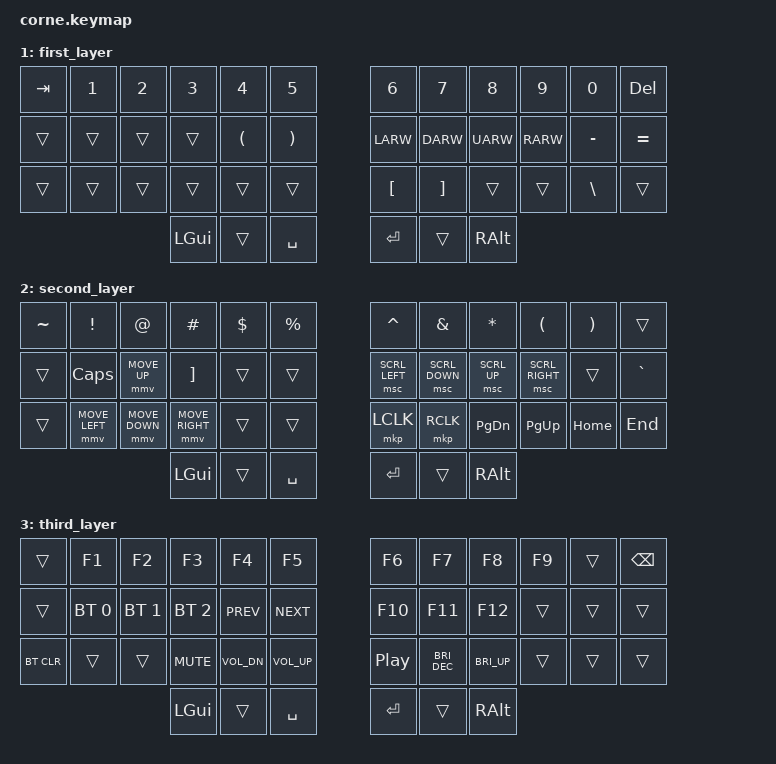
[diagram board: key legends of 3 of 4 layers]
/*
 * Copyright (c) 2020 The ZMK Contributors
 *
 * SPDX-License-Identifier: MIT
 */

#include <behaviors.dtsi>
#include <dt-bindings/zmk/keys.h>
#include <dt-bindings/zmk/bt.h>
#include <dt-bindings/zmk/outputs.h>
#include <dt-bindings/zmk/pointing.h>

// Home row mods macro
#define HRML(k1,k2,k3,k4) &ht LSHFT k1 &ht LCTRL k2  &ht LALT k3   &ht LGUI k4
#define HRMR(k1,k2,k3,k4) &ht RGUI k1  &ht LALT k2   &ht RCTRL k3  &ht RSHFT k4

#define DFLT 0
#define FRST 1
#define SCND 2
#define THRD 3

/ {
    behaviors {
         ht: hold_tap {
            label = "hold_tap";
            compatible = "zmk,behavior-hold-tap";
            #binding-cells = <2>;
            flavor = "tap-preferred";
            tapping-term-ms = <220>;
            quick-tap-ms = <150>;
            global-quick-tap;
            bindings = <&kp>, <&kp>;
        };
    };
        
    keymap {
            compatible = "zmk,keymap";

            default_layer {
    // -----------------------------------------------------------------------------------------
    // | ESC  |  Q  |  W  |  E  |  R  |  T  |   |  Y  |  U   |  I  |  O  |  P  | BSPC |
    // | SHFT |  A  |  S  |  D  |  F  |  G  |   |  H  |  J   |  K  |  L  |  ;  |  '   |
    // | CTRL |  Z  |  X  |  C  |  V  |  B  |   |  N  |  M   |  ,  |  .  |  /  | ENT  |
    //                    | GUI | LWR | SPC |   | ENT | RSE  | ALT |
                        bindings = <
    &kp ESC    &kp Q &kp W &kp E &kp R &kp T             &kp Y &kp U   &kp I      &kp O   &kp P    &kp BSPC
    &kp LSHFT HRML(A,   S,    D,   F) &kp G             &kp H HRMR(J,     K,         L,   SEMI)   &kp SQT
    &kp LCTRL &kp Z &kp X &kp C &kp V &kp B             &kp N &kp M   &kp COMMA  &kp PERIOD &kp FSLH &kp RET
                  &kp LGUI &mo FRST    &lt THRD SPACE   &kp RET &mo SCND &kp RALT
                        >;
                };
                first_layer {
    // -----------------------------------------------------------------------------------------
    // |  TAB |  1   |  2  |  3  |  4  |  5  |   |  6  |  7  |  8  |  9  |  0  | DEL  |
    // |      |      |     |     |  (  |  )  |   | LFT | DWN |  UP | RGT |  -_ |  +=  |
    // | SHFT |      |     |     |     |     |   |  [  |  ]  |     |     |  /| |      |
    //                    | GUI |     | SPC |   | ENT |     | ALT |
                        bindings = <
    &kp TAB    &kp N1    &kp N2    &kp N3     &kp N4       &kp N5         &kp N6   &kp N7    &kp N8   &kp N9    &kp N0    &kp DEL
    &trans     &trans  &trans    &trans     &kp LPAR     &kp RPAR       &kp LARW &kp DARW  &kp UARW &kp RARW  &kp MINUS &kp EQUAL
    &trans     &trans    &trans    &trans     &trans       &trans         &kp LBKT &kp RBKT &trans   &trans    &kp BSLH     &trans
                                   &kp LGUI     &trans     &kp SPACE    &kp RET  &trans   &kp RALT
                        >;
                };
                second_layer {
    // -----------------------------------------------------------------------------------------
    // |  ˜   |  !    |  @    |  #     |  $  |  %  |   |  ^        |  &         |  *      |  (           |  )  |      |
    // |      | CAPS  |  M_UP |        |     |     |   | SCRL_LEFT | SCRL_DOWN  | SCRL_UP | SCRL_RIGHT   |     |  `   |
    // |      |  M_LT |  M_DN |  M_RT  |     |     |   | M_LEFT    | M_RIGHT    | PG DOWN | PG UP        |  ~   |
    //                    | GUI |     | SPC |   | ENT |            | ALT     |
                        bindings = <
    &kp TILDE &kp EXCL        &kp AT          &kp HASH         &kp DLLR &kp PRCNT   &kp CARET         &kp AMPS          &kp ASTRK       &kp LPAR          &kp RPAR &trans
    &trans    &kp CAPS        &mmv MOVE_UP    &kp RBKT         &trans   &trans      &msc SCRL_LEFT    &msc SCRL_DOWN    &msc SCRL_UP    &msc SCRL_RIGHT   &trans   &kp GRAVE
    &trans    &mmv MOVE_LEFT  &mmv MOVE_DOWN  &mmv MOVE_RIGHT  &trans   &trans      &mkp LCLK         &mkp RCLK         &kp PG_DN       &kp PG_UP            &kp HOME &kp END
                              &kp LGUI &trans   &kp SPACE   &kp RET   &trans    &kp RALT
                        >;
                };

                third_layer {
    // --------------------------------------------------------------------------------------------------
    // |        |  F1 |  F2 |  F3  |  F4  |  F5   |   |  F6    | F7      | F8        | F9  |     | BSPC |
    // |        | BT0 | BT1 | BT2  | PREV | NXT   |   | F10    | F11     | F12       |     |     |      |
    // | BT_CLR |     |     | VMUT | VDWN | VUP   |   | PAUSE  | -BRIGHT |  +BRIGHT  |     |     |      |
    //                    | GUI |     | SPC |   | ENT |     | ALT |
                        bindings = <
    &trans      &kp F1       &kp F2       &kp F3         &kp F4            &kp F5         &kp F6           &kp F7          &kp F8          &kp F9  &trans &kp BSPC
    &trans      &bt BT_SEL 0 &bt BT_SEL 1 &bt BT_SEL 2   &kp C_PREV        &kp C_NEXT     &kp F10          &kp F11         &kp F12         &trans  &trans &trans
    &bt BT_CLR  &trans       &trans       &kp C_MUTE     &kp C_VOL_DN      &kp C_VOL_UP   &kp C_PP         &kp C_BRI_DEC   &kp C_BRI_UP    &trans  &trans &trans
                                  &kp LGUI     &trans       &kp SPACE   &kp RET  &trans   &kp RALT
                        >;
                };

        };
};
